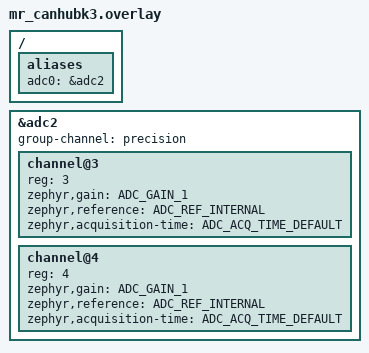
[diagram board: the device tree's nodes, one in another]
/*
 * Copyright (c) 2024 Centro de Inovacao EDGE
 *
 * SPDX-License-Identifier: Apache-2.0
 */

#include <zephyr/dt-bindings/adc/adc.h>

/ {
	aliases {
		adc0 = &adc2;
	};
};

&adc2 {
	group-channel = "precision";
	status = "okay";
	#address-cells = <1>;
	#size-cells = <0>;

	channel@3 {
		reg = <3>;
		zephyr,gain = "ADC_GAIN_1";
		zephyr,reference = "ADC_REF_INTERNAL";
		zephyr,acquisition-time = <ADC_ACQ_TIME_DEFAULT>;
	};

	channel@4 {
		reg = <4>;
		zephyr,gain = "ADC_GAIN_1";
		zephyr,reference = "ADC_REF_INTERNAL";
		zephyr,acquisition-time = <ADC_ACQ_TIME_DEFAULT>;
	};
};
